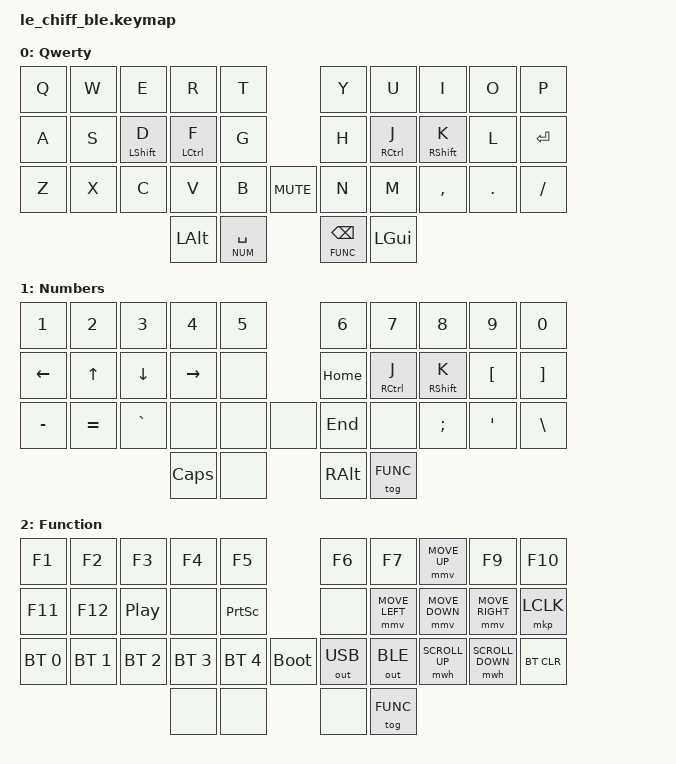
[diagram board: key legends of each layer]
/*
 * Copyright (c) 2023 @Lunaristic
 *
 * SPDX-License-Identifier: MIT
 */

#include <behaviors.dtsi>
#include <dt-bindings/zmk/keys.h>
#include <dt-bindings/zmk/bt.h>
#include <dt-bindings/zmk/outputs.h>
#include <dt-bindings/zmk/mouse.h>

#define QWRT 0
#define NUMB 1
#define FUNC 2

#define U_MOUSE_MOVE_MAX 1600                     /* <--- New max speed setting (default: 600) */
#undef MOVE_UP
#undef MOVE_DOWN
#undef MOVE_LEFT
#undef MOVE_RIGHT
#define MOVE_UP MOVE_VERT(-U_MOUSE_MOVE_MAX)
#define MOVE_DOWN MOVE_VERT(U_MOUSE_MOVE_MAX)
#define MOVE_LEFT MOVE_HOR(-U_MOUSE_MOVE_MAX)
#define MOVE_RIGHT MOVE_HOR(U_MOUSE_MOVE_MAX)

#define U_MOUSE_SCROLL_MAX 15                    /* <--- New max speed setting (default: 10) */

#undef SCROLL_UP
#undef SCROLL_DOWN
#undef SCROLL_LEFT
#undef SCROLL_RIGHT
#define SCROLL_UP SCROLL_VERT(U_MOUSE_SCROLL_MAX)
#define SCROLL_DOWN SCROLL_VERT(-U_MOUSE_SCROLL_MAX)
#define SCROLL_LEFT SCROLL_HOR(-U_MOUSE_SCROLL_MAX)
#define SCROLL_RIGHT SCROLL_HOR(U_MOUSE_SCROLL_MAX)

&mwh {
	time-to-max-speed-ms = <0>;                 
};
&mmv {
	time-to-max-speed-ms = <300>;             
};

&lt {
	quick_tap_ms = <200>;
};

&caps_word {
	continue-list = <UNDERSCORE MINUS BSPC LSHFT RSHFT>;
};

//  _____________________________       _____________________________
// /  0  |  1  |  2  |  3  |  4  \     /   5 |   6 |   7 |   8 |  9  \
// | 10  | 11  | 12  | 13  | 14  | ___ |  15 |  16 |  17 |  18 | 19  |
// | 20  | 21  | 22  | 23  | 24  ||025||  26 |  27 |  28 |  29 | 30  |
//          \   31   |    32     /     \     33    |  34    /
//           --------------------       --------------------

/ {
	macros {
		macro_cut: macro_cut {
			label = "macro_cut";
			compatible = "zmk,behavior-macro";
			#binding-cells = <0>;
			bindings
				= <&macro_press &kp LCTRL>
				, <&macro_tap &kp X>
                , <&macro_release &kp LCTRL>
                ;
		};
		macro_copy: macro_copy {
			label = "macro_copy";
			compatible = "zmk,behavior-macro";
			#binding-cells = <0>;
			bindings
				= <&macro_press &kp LCTRL>
				, <&macro_tap &kp C>
                , <&macro_release &kp LCTRL>
                ;
		};
		macro_paste: macro_paste {
			label = "macro_paste";
			compatible = "zmk,behavior-macro";
			#binding-cells = <0>;
			bindings
				= <&macro_press &kp LCTRL>
				, <&macro_tap &kp V>
                , <&macro_release &kp LCTRL>
                ;
		};
	};

	combos {
		compatible = "zmk,combos";
		combo_esc {
			timeout-ms = <20>;
			key-positions = <0 1>;
			bindings = <&kp ESC>;
			layers = <QWRT>;
		};
		combo_del {
			timeout-ms = <20>;
			key-positions = <1 2>;
			bindings = <&kp DEL>;
			layers = <QWRT>;
		};
		combo_tab {
			timeout-ms = <20>;
			key-positions = <10 11>;
			bindings = <&kp TAB>;
			layers = <QWRT>;
		};
		combo_cut {
			timeout-ms = <20>;
			key-positions = <20 21>;
			bindings = <&macro_cut>;
			layers = <QWRT>;
		};
		combo_copy {
			timeout-ms = <20>;
			key-positions = <21 22>;
			bindings = <&macro_copy>;
			layers = <QWRT>;
		};
		combo_paste {
			timeout-ms = <20>;
			key-positions = <22 23>;
			bindings = <&macro_paste>;
			layers = <QWRT>;
		};
	};

	behaviors {
		hm: homerow_mods {
			compatible = "zmk,behavior-hold-tap";
			label = "homerow mods";
			#binding-cells = <2>;
			flavor = "tap-preferred";
			tapping-term-ms = <200>;
			quick-tap-ms = <100>;
			bindings = <&kp>, <&kp>;
		};
	};
	
	keymap {
		compatible = "zmk,keymap";

		default_layer {
			label = "Qwerty";
			bindings = <
			&kp Q		&kp W		&kp E		&kp R		&kp T					&kp Y		&kp U		&kp I		&kp O		&kp P
			&kp A		&kp S		&hm LSHFT D	&hm LCTRL F	&kp G					&kp H		&hm RCTRL J	&hm RSHFT K	&kp L		&kp RET
			&kp Z		&kp X		&kp C		&kp V		&kp B		&kp C_MUTE	&kp N		&kp M		&kp COMMA	&kp DOT		&kp FSLH
												&kp LALT	&lt NUM SPACE			&lt FUNC BSPC	&kp LGUI
			>;
			sensor-bindings = <&inc_dec_kp C_VOL_DN C_VOL_UP>;
		};

		numbers_layer {
			label = "Numbers";
			bindings = <
			&kp N1		&kp N2		&kp N3		&kp N4		&kp N5					&kp N6		&kp N7		&kp N8		&kp N9		&kp N0
			&kp LEFT	&kp UP		&kp DOWN	&kp RIGHT	&none					&kp HOME	&hm RCTRL J	&hm RSHFT K	&kp LBKT	&kp RBKT
			&kp MINUS	&kp EQUAL	&kp GRAVE	&none		&none		&none		&kp END		&none		&kp SEMI	&kp SQT		&kp BSLH
												&kp CAPS	&none					&kp RALT	&tog FUNC
			>;
			sensor-bindings = <&inc_dec_kp C_VOL_DN C_VOL_UP>;
		};
		
		functions_layer {
			label = "Function";
			bindings = <
			&kp F1			&kp F2			&kp F3			&kp F4			&kp F5									&kp F6			&kp F7			&mmv MOVE_UP	&kp F9				&kp F10
			&kp F11			&kp F12			&kp C_PP		&none			&kp PSCRN								&none			&mmv MOVE_LEFT	&mmv MOVE_DOWN	&mmv MOVE_RIGHT		&mkp LCLK
			&bt BT_SEL 0	&bt BT_SEL 1	&bt BT_SEL 2	&bt BT_SEL 3	&bt BT_SEL 4		&bootloader			&out OUT_USB	&out OUT_BLE	&mwh SCROLL_UP	&mwh SCROLL_DOWN	&bt BT_CLR
															&none			&none									&none			&tog FUNC
			>;
			sensor-bindings = <&inc_dec_kp C_VOL_DN C_VOL_UP>;
		};
	};
};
